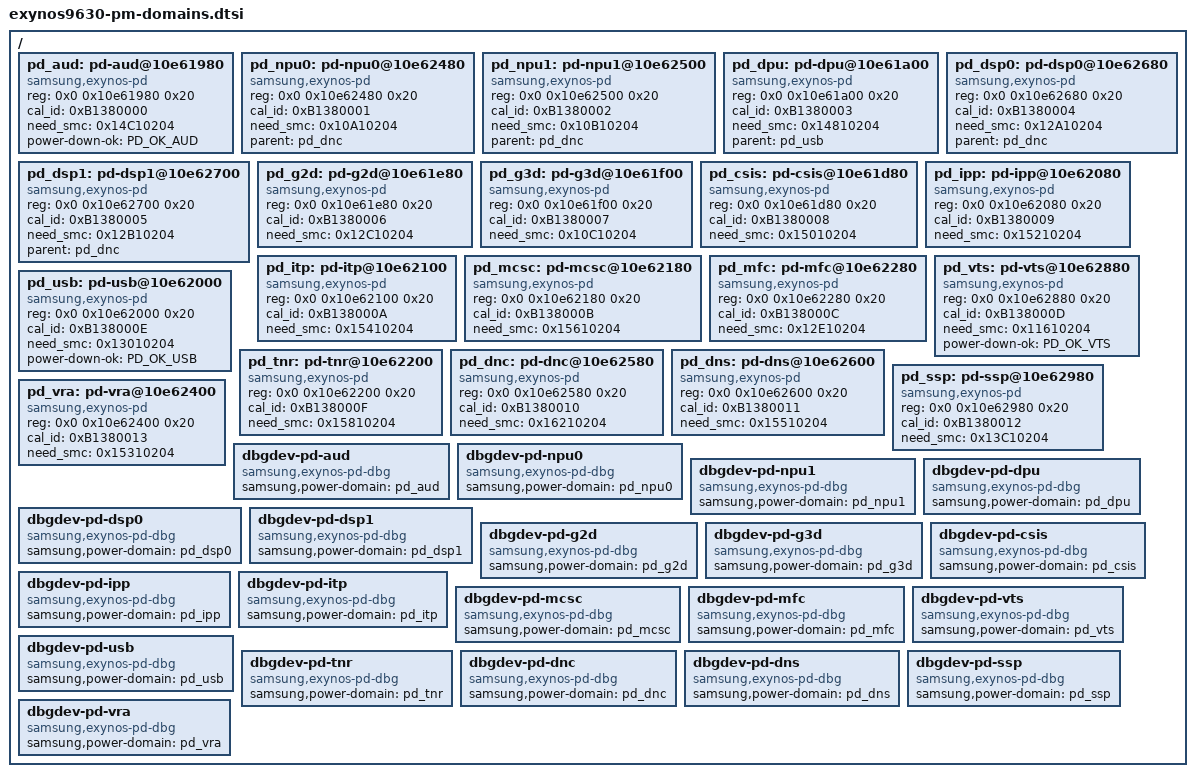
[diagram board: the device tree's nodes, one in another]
/*
* SAMSUNG EXYNOS9810 SoC PM Domains device tree source
*
* Copyright (c) 2017 Samsung Electronics Co., Ltd.
*		http://www.samsung.com
*
* SAMSUNG EXYNOS9810 SoC PM domains device nodes are listed in this file.
* EXYNOS9810 based board files can include this file and provide
* values for board specfic bindings.
*
* This program is free software; you can redistribute it and/or modify
* it under the terms of the GNU General Public License version 2 as
* published by the Free Software Foundation.
*/

#include <dt-bindings/power/exynos-power.h>

/ {
	pd_aud: pd-aud@10e61980 {
		compatible = "samsung,exynos-pd";
		reg = <0x0 0x10e61980 0x20>;
		cal_id = <0xB1380000>;
		need_smc = <0x14C10204>;
		status = "okay";
		power-down-ok = <PD_OK_AUD>;
	};

	pd_npu0: pd-npu0@10e62480 {
		 compatible = "samsung,exynos-pd";
		 reg = <0x0 0x10e62480 0x20>;
		 cal_id = <0xB1380001>;
		 need_smc = <0x10A10204>;
		 status = "okay";
		 parent = <&pd_dnc>;
	 };

	pd_npu1: pd-npu1@10e62500 {
		 compatible = "samsung,exynos-pd";
		 reg = <0x0 0x10e62500 0x20>;
		 cal_id = <0xB1380002>;
		 need_smc = <0x10B10204>;
		 status = "okay";
		 parent = <&pd_dnc>;
	 };

	pd_dpu: pd-dpu@10e61a00 {
		compatible = "samsung,exynos-pd";
		reg = <0x0 0x10e61a00 0x20>;
		cal_id = <0xB1380003>;
		need_smc = <0x14810204>;
		status = "okay";
		parent = <&pd_usb>;
	};

	pd_dsp0: pd-dsp0@10e62680 {
		 compatible = "samsung,exynos-pd";
		 reg = <0x0 0x10e62680 0x20>;
		 cal_id = <0xB1380004>;
		 need_smc = <0x12A10204>;
		 status = "okay";
		 parent = <&pd_dnc>;
	 };

	pd_dsp1: pd-dsp1@10e62700 {
		 compatible = "samsung,exynos-pd";
		 reg = <0x0 0x10e62700 0x20>;
		 cal_id = <0xB1380005>;
		 need_smc = <0x12B10204>;
		 status = "okay";
		 parent = <&pd_dnc>;
	 };

	pd_g2d: pd-g2d@10e61e80 {
		compatible = "samsung,exynos-pd";
		reg = <0x0 0x10e61e80 0x20>;
		cal_id = <0xB1380006>;
		need_smc = <0x12C10204>;
		status = "okay";
	};

	pd_g3d: pd-g3d@10e61f00 {
		compatible = "samsung,exynos-pd";
		reg = <0x0 0x10e61f00 0x20>;
		cal_id = <0xB1380007>;
		need_smc = <0x10C10204>;
		status = "okay";
	};

	pd_csis: pd-csis@10e61d80 {
		 compatible = "samsung,exynos-pd";
		 reg = <0x0 0x10e61d80 0x20>;
		 cal_id = <0xB1380008>;
		 need_smc = <0x15010204>;
		 status = "okay";
	 };

	pd_ipp: pd-ipp@10e62080 {
		compatible = "samsung,exynos-pd";
		reg = <0x0 0x10e62080 0x20>;
		cal_id = <0xB1380009>;
		need_smc = <0x15210204>;
		status = "okay";
	};

	pd_itp: pd-itp@10e62100 {
		compatible = "samsung,exynos-pd";
		reg = <0x0 0x10e62100 0x20>;
		cal_id = <0xB138000A>;
		need_smc = <0x15410204>;
		status = "okay";
	};

	pd_mcsc: pd-mcsc@10e62180 {
		 compatible = "samsung,exynos-pd";
		 reg = <0x0 0x10e62180 0x20>;
		 cal_id = <0xB138000B>;
		 need_smc = <0x15610204>;
		 status = "okay";
	 };

	pd_mfc: pd-mfc@10e62280 {
		compatible = "samsung,exynos-pd";
		reg = <0x0 0x10e62280 0x20>;
		cal_id = <0xB138000C>;
		need_smc = <0x12E10204>;
		status = "okay";
	};

	pd_vts: pd-vts@10e62880 {
		compatible = "samsung,exynos-pd";
		reg = <0x0 0x10e62880 0x20>;
		cal_id = <0xB138000D>;
		need_smc = <0x11610204>;
		status = "okay";
		power-down-ok = <PD_OK_VTS>;
	};

	pd_usb: pd-usb@10e62000 {
		compatible = "samsung,exynos-pd";
		reg = <0x0 0x10e62000 0x20>;
		cal_id = <0xB138000E>;
		need_smc = <0x13010204>;
		status = "okay";
		power-down-ok = <PD_OK_USB>;
	};

	pd_tnr: pd-tnr@10e62200 {
		compatible = "samsung,exynos-pd";
		reg = <0x0 0x10e62200 0x20>;
		cal_id = <0xB138000F>;
		need_smc = <0x15810204>;
		status = "okay";
	};

	pd_dnc: pd-dnc@10e62580 {
		compatible = "samsung,exynos-pd";
		reg = <0x0 0x10e62580 0x20>;
		cal_id = <0xB1380010>;
		need_smc = <0x16210204>;
		status = "okay";
	};

	pd_dns: pd-dns@10e62600 {
		compatible = "samsung,exynos-pd";
		reg = <0x0 0x10e62600 0x20>;
		cal_id = <0xB1380011>;
		need_smc = <0x15510204>;
		status = "okay";
	};

	pd_ssp: pd-ssp@10e62980 {
		compatible = "samsung,exynos-pd";
		reg = <0x0 0x10e62980 0x20>;
		cal_id = <0xB1380012>;
		need_smc = <0x13C10204>;
		status = "okay";
	};

	pd_vra: pd-vra@10e62400 {
		compatible = "samsung,exynos-pd";
		reg = <0x0 0x10e62400 0x20>;
		cal_id = <0xB1380013>;
		need_smc = <0x15310204>;
		status = "okay";
	};

	dbgdev-pd-aud {
		compatible = "samsung,exynos-pd-dbg";
		samsung,power-domain = <&pd_aud>;
	};

	dbgdev-pd-npu0 {
		compatible = "samsung,exynos-pd-dbg";
		samsung,power-domain = <&pd_npu0>;
	};

	dbgdev-pd-npu1 {
		compatible = "samsung,exynos-pd-dbg";
		samsung,power-domain = <&pd_npu1>;
	};

	dbgdev-pd-dpu {
		compatible = "samsung,exynos-pd-dbg";
		samsung,power-domain = <&pd_dpu>;
	};

	dbgdev-pd-dsp0 {
		compatible = "samsung,exynos-pd-dbg";
		samsung,power-domain = <&pd_dsp0>;
	};

	dbgdev-pd-dsp1 {
		compatible = "samsung,exynos-pd-dbg";
		samsung,power-domain = <&pd_dsp1>;
	};

	dbgdev-pd-g2d {
		compatible = "samsung,exynos-pd-dbg";
		samsung,power-domain = <&pd_g2d>;
	};

	dbgdev-pd-g3d {
		compatible = "samsung,exynos-pd-dbg";
		samsung,power-domain = <&pd_g3d>;
	};

	dbgdev-pd-csis {
		compatible = "samsung,exynos-pd-dbg";
		samsung,power-domain = <&pd_csis>;
	};

	dbgdev-pd-ipp {
		compatible = "samsung,exynos-pd-dbg";
		samsung,power-domain = <&pd_ipp>;
	};

	dbgdev-pd-itp {
		compatible = "samsung,exynos-pd-dbg";
		samsung,power-domain = <&pd_itp>;
	};

	dbgdev-pd-mcsc {
		compatible = "samsung,exynos-pd-dbg";
		samsung,power-domain = <&pd_mcsc>;
	};

	dbgdev-pd-mfc {
		compatible = "samsung,exynos-pd-dbg";
		samsung,power-domain = <&pd_mfc>;
	};

	dbgdev-pd-vts {
		compatible = "samsung,exynos-pd-dbg";
		samsung,power-domain = <&pd_vts>;
	};

	dbgdev-pd-usb {
		compatible = "samsung,exynos-pd-dbg";
		samsung,power-domain = <&pd_usb>;
	};

	dbgdev-pd-tnr {
		compatible = "samsung,exynos-pd-dbg";
		samsung,power-domain = <&pd_tnr>;
	};

	dbgdev-pd-dnc {
		compatible = "samsung,exynos-pd-dbg";
		samsung,power-domain = <&pd_dnc>;
	};

	dbgdev-pd-dns {
		compatible = "samsung,exynos-pd-dbg";
		samsung,power-domain = <&pd_dns>;
	};

	dbgdev-pd-ssp {
		compatible = "samsung,exynos-pd-dbg";
		samsung,power-domain = <&pd_ssp>;
	};

	dbgdev-pd-vra {
		compatible = "samsung,exynos-pd-dbg";
		samsung,power-domain = <&pd_vra>;
	};
};

